# YTM32B1LE1 register map
Vendor: YTMicro; File version: 1.0
CPU: CM0PLUS r0p1, little endian, MPU, FPU, 2 interrupt priority bits
Registers are 32-bit, read-write, reset 0x0 unless marked. A register's access mark holds for its fields unless they carry their own. Offsets are from the block's base; [hi:lo] are bit positions; 'fields as' and 'values as' point back to an identical list.

## EMU0 — ECC Management Unit
Base 0x40018000; register names take the prefix EMU0_
0x00 EIGCR
  [31:0] GEN — This bit will enable or disable all error injection functions. Write 0x89abcdef will enable this function. Read 0 means, global error injection is disabled Read 1 means, global error injection is enabled
0x04 EICHCR
  [0] CHEN — This field enable or disable channel n error injection function. Enable channel n error injection function should enable this field and EIGCR[GEN]. Any write to EICHDn_ADDR, EICHDn_CHKBIT, EICHDn_DATA register will clear this field. 0b - Channel n error injection is disabled 1b - Channel n error injection is enabled
0x10 EICHD0_ADDR
  [31:0] ADDR — This field defines which address will be injected error when read access. when the ADDR is not 0, error will be injected according to this field's value. If ADDR is 0xFFFFFFFF, Error will be injected at all read access.
0x14 EICHD0_CHKBIT — The checkbit can only support injecting error in fixed positions, the mask data is 0x04.
  [6:0] CHKBIT — This field defines a bit-mapped mask that specifies whether the corresponding bit of the checkbit bus from the target on-chip memory should be inverted or remain unmodified. ewline 0b - The corresponding bit of the checkbit bus remains unmodified. ewline 1b - The corresponding bit of the checkbit bus is inverted.
0x18 EICHD0_DATA — The databit can only support injecting error in fixed positions, the mask data is 0x00000002.
  [31:0] DATA — This field defines a bit-mapped mask that specifies whether the corresponding bit of the read data bus from the target on-chip memory should be inverted or remain unmodified. ewline 0b - The corresponding bit of the databit bus remains unmodified. ewline 1b - The corresponding bit of the databit bus is inverted.
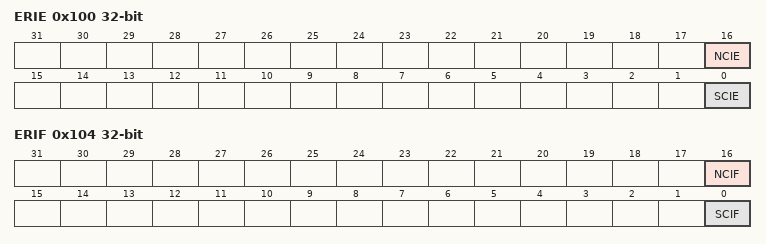
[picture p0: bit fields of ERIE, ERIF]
0x100 ERIE
  [16] NCIE — Non-Correctable error interrupt enable. 0b - Channel n Non-Correctable Error interrupt is disabled 1b - Channel n Non-Correctable Error interrupt is enabled
  [0] SCIE — Single correctable error interrupt enable 0b - Channel n Single Correctable Error interrupt is disabled 1b - Channel n Single Correctable Error interrupt is enabled
0x104 ERIF — This register is reset by Power-on Reset.
  [16] NCIF — Non-Correctable error interrupt flag. NCIF flag is kept when software reset but cleared when POR. 0b - Channel n Non-Correctable Error interrupt not detected 1b - Channel n Non-Correctable Error interrupt detected
  [0] SCIF — Single Correctable error interrupt flag. SCIF flag is kept when software reset but cleared when POR. 0b - Channel n Single Correctable Error interrupt not detected 1b - Channel n Single Correctable Error interrupt detected
0x110 ERINFO0_ADDR ro — This register is reset by Power-on Reset.
  [31:0] ADDR — This field contains the faulting system address of the last recorded ECC event on on-chip memories.
0x114 ERINFO0_SYND ro — This register is reset by Power-on Reset.
  [6:0] SYNDROME — This field contains the syndrome of the last recorded ECC event on on-chip memories.
0x118 ERINFO0_CNT wo — This register is reset by Power-on Reset.
  [7:0] CNT rw — For each correctable error event, the EMU increments this field's error count value until the counter reaches its maximum value 0xFF. CNT will not change once it reaches 0xFF and will not wrap even if error occurs. Read this field to determine the correctable error count value so far. Write zero to this field to reset the counter. Writing non-zero (or partial zero) values has no effect.

## CMU0 — Clock monitor unit
Base 0x40078000; register names take the prefix CMU0_
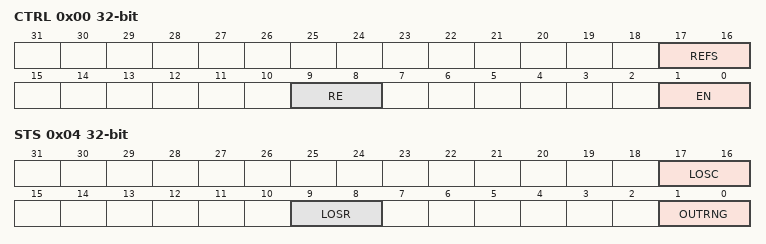
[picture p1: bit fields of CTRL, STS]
0x00 CTRL — System Clock Unit Clock Monitor Unit control register
  [17:16] REFS — The reference clock of each CMU channel can be configured independently. Channel 1 monitor FXOSC clock, only SIRC clock can be used as reference clock. For other channels, reference clock can select between SIRC clock and FXOSC clock. For each bit of CMU_REFS except for bit[1] : 0b - The indexed channel select SIRC clock as reference clock; 1b - The indexed channel select FXOSC clock as reference clock.
  [9:8] RE — The reset of each CMU channel can be configured independently. For each bit of CMU_RE: 0b - Interrupt is generated when the indexed channel monitored clock is out of range; 1b - Reset is generated when the indexed channel monitored clock is out of range.
  [1:0] EN — CMU has 2 channels to monitor internal clock. Each CMU channel can be enable or disabled independently. For each bit of CMU_EN: 0b - The indexed channel is disabled; 1b - The indexed channel is enabled
0x04 STS — System Clock Unit Clock Monitor Unit status register. This register is reset by Power-on Reset.
  [17:16] LOSC — CMU_LOSC[i]=1 (i=0~1) means channel i loss of monitored clock. This register is reset by Power-on Reset.
  [9:8] LOSR — CMU_LOSR[i]=1 (i=0~1) means channel i loss of reference clock. This register is reset by Power-on Reset.
  [1:0] OUTRNG — CMU_OUTRNG[i]=1 (i=0~1) means channel i monitored clock out of range. This register is reset by Power-on Reset.
0x08 CMP0_HIGH reset 0xFFFF — Clock Monitor High Comparison Value Register.
  [15:0] VAL
0x0C CMP0_LOW — Clock Monitor Low Comparison Value Register
  [15:0] VAL
0x10 CMP1_HIGH reset 0xFFFF — Clock Monitor High Comparison Value Register.
  [15:0] VAL
0x14 CMP1_LOW — Clock Monitor Low Comparison Value Register
  [15:0] VAL
0x48 REFCNTTGT0 reset 0x7F — Reference Clock Counter Target Value Register for Each CMU Channel
  [7:0] VAL — The sample window of CMU channel n is (REFCNTTGTn+1) reference clock cycles. Internal monitered clock counter value is campared to CMP.HIGH and CMP.LOW at end of each sample window.
0x4C REFCNTTGT1 reset 0x7F — Reference Clock Counter Target Value Register for Each CMU Channel
  fields as REFCNTTGT0
